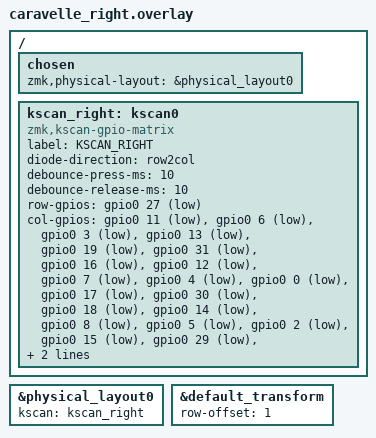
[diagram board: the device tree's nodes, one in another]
#include <dt-bindings/zmk/matrix_transform.h>
#include "caravelle.dtsi"

/ {
    chosen {
        zmk,physical-layout = &physical_layout0;
    };

    /* Right-hand specific kscan (overrides shared definition) */
    kscan_right: kscan0 {
        compatible = "zmk,kscan-gpio-matrix";
        label = "KSCAN_RIGHT";
        diode-direction = "row2col";
        debounce-press-ms = <10>;
        debounce-release-ms = <10>;

        /* Row Pin: P0.27 (QMK mapping) */
        row-gpios = <&gpio0 27 (GPIO_ACTIVE_LOW)>;

        /* Col Pins: QMK mapping (24 cols) */
        col-gpios = <&gpio0 11 (GPIO_ACTIVE_LOW | GPIO_PULL_UP)>,
                   <&gpio0 6  (GPIO_ACTIVE_LOW | GPIO_PULL_UP)>,
                   <&gpio0 3   (GPIO_ACTIVE_LOW | GPIO_PULL_UP)>,
                   <&gpio0 13   (GPIO_ACTIVE_LOW | GPIO_PULL_UP)>,
                   <&gpio0 19  (GPIO_ACTIVE_LOW | GPIO_PULL_UP)>,
                   <&gpio0 31  (GPIO_ACTIVE_LOW | GPIO_PULL_UP)>,
                   <&gpio0 16  (GPIO_ACTIVE_LOW | GPIO_PULL_UP)>,
                   <&gpio0 12  (GPIO_ACTIVE_LOW | GPIO_PULL_UP)>,
                   <&gpio0 7  (GPIO_ACTIVE_LOW | GPIO_PULL_UP)>,
                   <&gpio0 4   (GPIO_ACTIVE_LOW | GPIO_PULL_UP)>,
                   <&gpio0 0   (GPIO_ACTIVE_LOW | GPIO_PULL_UP)>,
                   <&gpio0 17   (GPIO_ACTIVE_LOW | GPIO_PULL_UP)>,
                   <&gpio0 30  (GPIO_ACTIVE_LOW | GPIO_PULL_UP)>,
                   <&gpio0 18  (GPIO_ACTIVE_LOW | GPIO_PULL_UP)>,
                   <&gpio0 14  (GPIO_ACTIVE_LOW | GPIO_PULL_UP)>,
                   <&gpio0 8   (GPIO_ACTIVE_LOW | GPIO_PULL_UP)>,
                   <&gpio0 5   (GPIO_ACTIVE_LOW | GPIO_PULL_UP)>,
                   <&gpio0 2   (GPIO_ACTIVE_LOW | GPIO_PULL_UP)>,
                   <&gpio0 15  (GPIO_ACTIVE_LOW | GPIO_PULL_UP)>,
                   <&gpio0 29  (GPIO_ACTIVE_LOW | GPIO_PULL_UP)>,
                   <&gpio0 24  (GPIO_ACTIVE_LOW | GPIO_PULL_UP)>,
                   <&gpio0 23  (GPIO_ACTIVE_LOW | GPIO_PULL_UP)>,
                   <&gpio0 22  (GPIO_ACTIVE_LOW | GPIO_PULL_UP)>,
                   <&gpio0 20  (GPIO_ACTIVE_LOW | GPIO_PULL_UP)>;
    };
};

&physical_layout0 {
    kscan = <&kscan_right>;
};

&default_transform {
   row-offset = <1>;
};
